# ESM register map
Vendor: Texas Instruments
Peripheral module from a debugger description file (folder TDA3x).
Registers are 32-bit, read-write, reset 0x0 unless marked. A register's access mark holds for its fields unless they carry their own. Offsets are as the file gives them; lines under a group give offsets from that group; [hi:lo] are bit positions; {n}, {i} and the like mark numbered series; 'fields as' and 'values as' point back to an identical list; <NAME> marks a mode.

## ESM
0x00 ESMIEPSR1 — ESM Influence Error Pin Set/Status Register 1
  [31:0] IEPSET — User and privilege mode (read): 0 = failure on channel x has no influence on error pin 1 = failure on channel x has influence on error pin Privilege mode (write): 0 = leaves the bit and the corresponding clear bit in theESMIEPCR1 register unchanged 1 = enables failure influence on error pin and sets the corresponding clear bit in the ESMIEPCR1 register
0x04 ESMIEPCR1 — ESM Influence Error Pin Clear/Status Register 1
  [31:0] IEPCLR — User and privilege mode (read): 0 = failure on channel x has no influence on error pin 1 = failure on channel x has influence on error pin Privilege mode (write): 0 = leaves the bit and the corresponding set bit in theESMIEPSR1 register unchanged 1 = disables failure influence on error pin and clears the corresponding set bit in the ESMIEPSR1 register
0x08 ESMIESR1 — ESM Interrupt Enable Set/Status Register 1
  [31:0] INTENSET — User and privilege mode (read): 0 = interrupt is disabled 1 = interrupt is enabled Privilege mode (write): 0 = leaves the bit and the corresponding clear bit in theESMIECR1 register unchanged 1 = enables interrupt and sets the corresponding clear bit in the ESMIECR1 register
0x0C ESMIECR1 — ESM Interrupt Enable Clear/Status Register 1
  [31:0] INTENCLR — User and privilege mode (read): 0 = interrupt is disabled 1 = interrupt is enabled Privilege mode (write): 0 = leaves the bit and the corresponding set bit in theESMIESR1 register unchanged 1 = disables interrupt and clears the corresponding set bit in the ESMIESR1 register
0x10 ESMILSR1 — ESM Interrupt Level Set/Status Register 1
  [31:0] INTLVLSET — User and privilege mode (read): 0 = interrupt of channel x is mapped to low level interrupt line 1 = interrupt of channel x is mapped to high level interrupt line Privilege mode (write): 0 = leaves the bit and the corresponding clear bit in theESMILCR1 register unchanged 1 = maps interrupt of channel x to high level interrupt line and sets the corresponding clear bit in the ESMILCR1 register
0x14 ESMILCR1 — ESM Interrupt Level Clear/Status Register 1
  [31:0] INTLVLCLR — User and privilege mode (read): 0 = interrupt of channel x is mapped to low level interrupt line 1 = interrupt of channel x is mapped to high level interrupt line Privilege mode (write): 0 = leaves the bit and the corresponding set bit in theESMILSR1 register unchanged 1 = maps interrupt of channel x to low level interrupt line and clears the corresponding set bit in the ESMILSR1 register
0x18 ESMSR1 — ESM Status Register 1
  [31:0] ESF — Provides status information on pending error. User and privilege mode (read): 0 = no error occurred; no interrupt is pending 1 = error occurred; interrupt is pending Privilege mode (write): 0 = leaves the bit unchanged 1 = clears the bit
0x1C ESMSR2 — ESM Status Register 2
  fields as ESMSR1
0x20 ESMSR3 — ESM Status Register 3
  [31:0] ESF — Provides status information on pending error. User and privilege mode (read): 0 = no error occurred 1 = error occurred Privilege mode (write): 0 = leaves the bit unchanged 1 = clears the bit
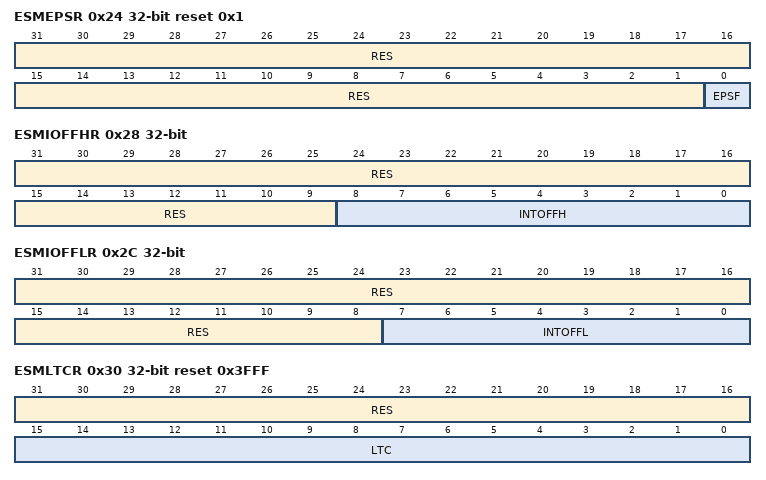
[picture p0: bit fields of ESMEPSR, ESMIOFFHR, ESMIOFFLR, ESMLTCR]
0x24 ESMEPSR ro reset 0x1 — ESM Error Pin Status Register
  [31:1] RES — Reads return 0 and writes have no effect
  [0] EPSF — Provides status information for the Error Pin. User and privilege mode (read): 0 = Error Pin is low (active) if any error has occurred 1 = Error Pin is high if no error has occurred User and privilege mode (write): Writes have no effect.
0x28 ESMIOFFHR ro — ESM Interrupt Offset High Register
  [31:9] RES — Reads return 0 and writes have no effect
  [8:0] INTOFFH — This vector gives the channel number of the highest pending interrupt request for the high level interrupt line. Interrupts of error group 2 have higher priority than interrupts of error group 1. Inside a group, channel 0 has highest priority and channel 63 has lowest priority. User and privilege mode (read): Returns number of pending interrupt with the highest priority for the high level interrupt line: 0000_0000 = no pending interrupt 0000_0001 = interrupt pending for channel 0, error group1 ... 0010_0000 = interrupt pending for channel 31, error group1 0010_0001 = interrupt pending for channel 0, error group2 ... 0100_0000 = interrupt pending for channel 31, error group2 0100_0001 = interrupt pending for channel 32, error group1 ... 0110_0000 = interrupt pending for channel 63, error group1 0110_0001 = interrupt pending for channel 32, error group2 ... 1000_0000 = interrupt pending for channel 63, error group2 1000_0001 = interrupt pending for channel 64, error group1 ... 1010_0000 = interrupt pending for channel 95, error group1 1010_0001 = interrupt pending for channel 64, error group2 ... 1100_0000 = interrupt pending for channel 95, error group2 1100_0001 = interrupt pending for channel 96, error group1 ... 1110_0000 = interrupt pending for channel 127, error group1 1110_0001 = interrupt pending for channel 96, error group2 ... 1_0000_0000 = interrupt pending for channel 127, error group2 Reading the interrupt vector will clear the corresponding flag in theESMSR2, ESMSR5, ESMSR8 and ESMSR11 registers and the offset register gets updated. User and privilege mode (write): Writes have no effect.
0x2C ESMIOFFLR ro — ESM Interrupt Offset Low Register
  [31:8] RES — Reads return 0 and writes have no effect
  [7:0] INTOFFL — This vector gives the channel number of the highest pending interrupt request for the low level interrupt line. Inside a group, channel 0 has highest priority and channel 63 has lowest priority. User and privilege mode (read): Returns number of pending interrupt with the highest priority for the low level interrupt line: 0000_0000 = no pending interrupt 0000_0001 = interrupt pending for channel 0, error group1 ... 0010_0000 = interrupt pending for channel 31, error group1 0100_0001 = interrupt pending for channel 32, error group1 ... 0110_0000 = interrupt pending for channel 63, error group1 1000_0001 = interrupt pending for channel 64, error group1 ... 1010_0000 = interrupt pending for channel 95, error group1 1100_0001 = interrupt pending for channel 96, error group1 ... 1110_0000 = interrupt pending for channel 127, error group1 Group2 interrupts are fixed to the high level interrupt line only. User and privilege mode (write): Writes have no effect.
0x30 ESMLTCR ro reset 0x3FFF — ESM Low-Time Counter Register
  [31:16] RES — Reads return 0 and writes have no effect
  [15:0] LTC — 16bit pre-loadable down-counter to control low-time of error pin. The lowtime counter is triggered by the peripheral clock (VCLK). Note: After reset the low time counter is set to the default preload value of theESMLTCPR to ensure a minimum low time of 100us running at a maximum frequency of 100MHz.
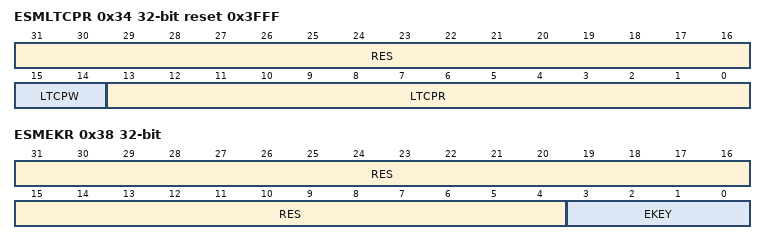
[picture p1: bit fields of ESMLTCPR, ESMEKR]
0x34 ESMLTCPR access per field reset 0x3FFF — ESM Low-Time Counter Preload Register
  [31:16] RES ro — Reads return 0 and writes have no effect
  [15:14] LTCPW rw — LTCP.15 and LTCP.14 are configurable (privilege mode write) to ensure a minimum low time of 100us running at a maximum frequency of 100MHz.
  [13:0] LTCPR ro — pre-load value for the error pin low-time counter.
0x38 ESMEKR access per field — ESM Error Key Register
  [31:4] RES ro — Reads return 0 and writes have no effect
  [3:0] EKEY rw — Key to reset the error pin or to force an error on the error pin. User and privilege mode (read): Returns current value of the EKEY. Privilege mode (write): 0000 = activates normal mode (recommended default mode) 1010 = forces error on error pin 0101 = error pin will be set to high when the low time counter (LTC) has completed; then theESMEKR.EKEY bit will switch back to normal mode (EKEY = 0000). others = activates normal mode
0x3C ESMSSR2 — ESM Status Shadow Register 2
  [31:0] ESF — Shadow register for status information on pending error. User and privilege mode (read): 0 = no error occurred 1 = error occurred Privilege mode (write): 0 = leaves the bit unchanged 1 = clears the bit Note: Errors are stored until they are cleared by the software or at power-on reset (PORRST). In case of system failure with SYS_nRST, software can read the shadow registers to determine the source of pending G2 errors.
0x40 ESMIEPSR4 — ESM Influence Error Pin Set/Status Register 4
  [31:0] IEPSET — User and privilege mode (read): 0 = failure on channel x has no influence on error pin 1 = failure on channel x has influence on error pin Privilege mode (write): 0 = leaves the bit and the corresponding clear bit in theESMIEPCR4 register unchanged 1 = enables failure influence on error pin and sets the corresponding clear bit in the ESMIEPCR4 register
0x44 ESMIEPCR4 — ESM Influence Error Pin Clear/Status Register 4
  [31:0] IEPCLR — User and privilege mode (read): 0 = failure on channel x has no influence on error pin 1 = failure on channel x has influence on error pin Privilege mode (write): 0 = leaves the bit and the corresponding set bit in theESMIEPSR4 register unchanged 1 = disables failure influence on error pin and clears the corresponding set bit in the ESMIEPSR4 register
0x48 ESMIESR4 — ESM Interrupt Enable Set/Status Register 4
  [31:0] INTENSET — User and privilege mode (read): 0 = interrupt is disabled 1 = interrupt is enabled Privilege mode (write): 0 = leaves the bit and the corresponding clear bit in theESMIECR4 register unchanged 1 = enables interrupt and sets the corresponding clear bit in the ESMIECR4 register
0x4C ESMIECR4 — ESM Interrupt Enable Clear/Status Register 4
  [31:0] INTENCLR — User and privilege mode (read): 0 = interrupt is disabled 1 = interrupt is enabled Privilege mode (write): 0 = leaves the bit and the corresponding set bit in theESMIESR4 register unchanged 1 = disables interrupt and clears the corresponding set bit in the ESMIESR4 register
0x50 ESMILSR4 — ESM Interrupt Level Set/Status Register 4
  [31:0] INTLVLSET — User and privilege mode (read): 0 = interrupt of channel x is mapped to low level interrupt line 1 = interrupt of channel x is mapped to high level interrupt line Privilege mode (write): 0 = leaves the bit and the corresponding clear bit in theESMILCR4 register unchanged 1 = maps interrupt of channel x to high level interrupt line and sets the corresponding clear bit in the ESMILCR4 register
0x54 ESMILCR4 — ESM Interrupt Level Clear/Status Register 4
  [31:0] INTLVLCLR — User and privilege mode (read): 0 = interrupt of channel x is mapped to low level interrupt line 1 = interrupt of channel x is mapped to high level interrupt line Privilege mode (write): 0 = leaves the bit and the corresponding set bit in theESMILSR4 register unchanged 1 = maps interrupt of channel x to low level interrupt line and clears the corresponding set bit in the ESMILSR4 register
0x58 ESMSR4 — ESM Status Register 4
  fields as ESMSR1
0x5C ESMSR5 — ESM Status Register 5
  [31:0] ESF — Provides status information on pending error. User and privilege mode (read): 0 = no error occurred; no interrupt is pending 1 = error occurred; interrupt is pending Privilege mode (write): 0 = leaves the bit unchanged 1 = clears the bit Note: In normal operation the flag gets cleared when reading the appropriate vector in theESMIOFFHR offset register.
0x60 ESMSR6 — ESM Status Register 6
  fields as ESMSR3
0x64 ESMSSR5 — ESM Status Shadow Register 5
  fields as ESMSSR2
0x80 ESMIEPSR7 — ESM Influence Error Pin Set/Status Register 7
  [31:0] IEPSET — User and privilege mode (read): 0 = failure on channel x has no influence on error pin 1 = failure on channel x has influence on error pin Privilege mode (write): 0 = leaves the bit and the corresponding clear bit in theESMIEPCR7 register unchanged 1 = enables failure influence on error pin and sets the corresponding clear bit in the ESMIEPCR7 register
0x84 ESMIEPCR7 — ESM Influence Error Pin Clear/Status Register 7
  [31:0] IEPCLR — User and privilege mode (read): 0 = failure on channel x has no influence on error pin 1 = failure on channel x has influence on error pin Privilege mode (write): 0 = leaves the bit and the corresponding set bit in theESMIEPSR7 register unchanged 1 = disables failure influence on error pin and clears the corresponding set bit in the ESMIEPSR7 register
0x88 ESMIESR7 — ESM Interrupt Enable Set/Status Register 7
  [31:0] INTENSET — User and privilege mode (read): 0 = interrupt is disabled 1 = interrupt is enabled Privilege mode (write): 0 = leaves the bit and the corresponding clear bit in theESMIECR7 register unchanged 1 = enables interrupt and sets the corresponding clear bit in the ESMIECR7 register
0x8C ESMIECR7 — ESM Interrupt Enable Clear/Status Register 7
  [31:0] INTENCLR — User and privilege mode (read): 0 = interrupt is disabled 1 = interrupt is enabled Privilege mode (write): 0 = leaves the bit and the corresponding set bit in theESMIESR7 register unchanged 1 = disables interrupt and clears the corresponding set bit in the ESMIESR7 register
0x90 ESMILSR7 — ESM Interrupt Level Set/Status Register 7
  [31:0] INTLVLSET — User and privilege mode (read): 0 = interrupt of channel x is mapped to low level interrupt line 1 = interrupt of channel x is mapped to high level interrupt line Privilege mode (write): 0 = leaves the bit and the corresponding clear bit in theESMILCR7 register unchanged 1 = maps interrupt of channel x to high level interrupt line and sets the corresponding clear bit in the ESMILCR7 register
0x94 ESMILCR7 — ESM Interrupt Level Clear/Status Register 7
  [31:0] INTLVLCLR — User and privilege mode (read): 0 = interrupt of channel x is mapped to low level interrupt line 1 = interrupt of channel x is mapped to high level interrupt line Privilege mode (write): 0 = leaves the bit and the corresponding set bit in theESMILSR7 register unchanged 1 = maps interrupt of channel x to low level interrupt line and clears the corresponding set bit in the ESMILSR7 register
0x98 ESMSR7 — ESM Status Register 7
  fields as ESMSR1
0x9C ESMSR8 — ESM Status Register 8
  fields as ESMSR5
0xA0 ESMSR9 — ESM Status Register 9
  fields as ESMSR3
0xA4 ESMSSR8 — ESM Status Shadow Register 8
  fields as ESMSSR2
0xC0 ESMIEPSR10 — ESM Influence Error Pin Set/Status Register 10
  [31:0] IEPSET — User and privilege mode (read): 0 = failure on channel x has no influence on error pin 1 = failure on channel x has influence on error pin Privilege mode (write): 0 = leaves the bit and the corresponding clear bit in theESMIEPCR10 register unchanged 1 = enables failure influence on error pin and sets the corresponding clear bit in the ESMIEPCR10 register
0xC4 ESMIEPCR10 — ESM Influence Error Pin Clear/Status Register 10
  [31:0] IEPCLR — User and privilege mode (read): 0 = failure on channel x has no influence on error pin 1 = failure on channel x has influence on error pin Privilege mode (write): 0 = leaves the bit and the corresponding set bit in theESMIEPSR10 register unchanged 1 = disables failure influence on error pin and clears the corresponding set bit in the ESMIEPSR10 register
0xC8 ESMIESR10 — ESM Interrupt Enable Set/Status Register 10
  [31:0] INTENSET — User and privilege mode (read): 0 = interrupt is disabled 1 = interrupt is enabled Privilege mode (write): 0 = leaves the bit and the corresponding clear bit in theESMIECR10 register unchanged 1 = enables interrupt and sets the corresponding clear bit in the ESMIECR10 register
0xCC ESMIECR10 — ESM Interrupt Enable Clear/Status Register 10
  [31:0] INTENCLR — User and privilege mode (read): 0 = interrupt is disabled 1 = interrupt is enabled Privilege mode (write): 0 = leaves the bit and the corresponding set bit in theESMIESR10 register unchanged 1 = disables interrupt and clears the corresponding set bit in the ESMIESR10 register
0xD0 ESMILSR10 — ESM Interrupt Level Set/Status Register 10
  [31:0] INTLVLSET — User and privilege mode (read): 0 = interrupt of channel x is mapped to low level interrupt line 1 = interrupt of channel x is mapped to high level interrupt line Privilege mode (write): 0 = leaves the bit and the corresponding clear bit in theESMILCR10 register unchanged 1 = maps interrupt of channel x to high level interrupt line and sets the corresponding clear bit in the ESMILCR10 register
0xD4 ESMILCR10 — ESM Interrupt Level Clear/Status Register 10
  [31:0] INTLVLCLR — User and privilege mode (read): 0 = interrupt of channel x is mapped to low level interrupt line 1 = interrupt of channel x is mapped to high level interrupt line Privilege mode (write): 0 = leaves the bit and the corresponding set bit in theESMILSR10 register unchanged 1 = maps interrupt of channel x to low level interrupt line and clears the corresponding set bit in the ESMILSR10 register
0xD8 ESMSR10 — ESM Status Register 10
  fields as ESMSR1
0xDC ESMSR11 — ESM Status Register 11
  fields as ESMSR5
0xE0 ESMSR12 — ESM Status Register 12
  fields as ESMSR3
0xE4 ESMSSR11 — ESM Status Shadow Register 11
  fields as ESMSSR2
